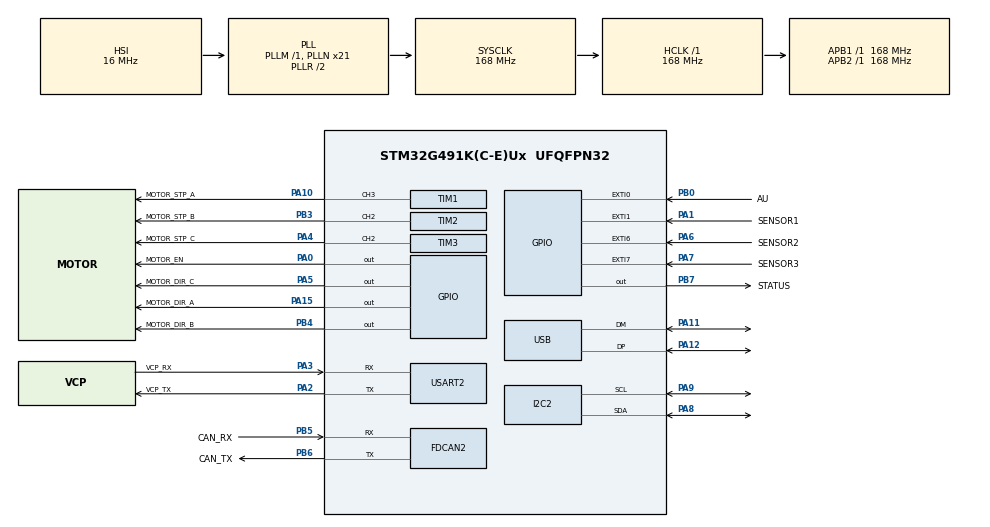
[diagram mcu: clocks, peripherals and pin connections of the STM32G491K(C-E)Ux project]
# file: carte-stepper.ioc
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FDCAN2.CalculateBaudRateNominal=3500000
FDCAN2.CalculateTimeBitNominal=285
FDCAN2.CalculateTimeQuantumNominal=95.23809523809524
I2C2.OwnAddress=0x69
I2C2.Timing=0x50916E9F
Mcu.Family=STM32G4
Mcu.Name=STM32G491K(C-E)Ux
Mcu.Package=UFQFPN32
NVIC.EXTI1_IRQn=true\:0\:0\:false\:false\:true\:true\:true\:true
NVIC.EXTI9_5_IRQn=true\:0\:0\:false\:false\:true\:true\:true\:true
NVIC.I2C2_ER_IRQn=true\:0\:0\:false\:false\:true\:true\:true\:true
NVIC.I2C2_EV_IRQn=true\:0\:0\:false\:false\:true\:true\:true\:true
NVIC.PriorityGroup=NVIC_PRIORITYGROUP_4
NVIC.TIM1_BRK_TIM15_IRQn=true\:0\:0\:false\:false\:true\:true\:true\:true
NVIC.TIM1_UP_TIM16_IRQn=true\:0\:0\:false\:false\:true\:true\:true\:true
NVIC.TIM20_UP_IRQn=true\:0\:0\:false\:false\:true\:true\:true\:true
NVIC.TIM2_IRQn=true\:0\:0\:false\:false\:true\:true\:true\:true
NVIC.TIM3_IRQn=true\:0\:0\:false\:false\:true\:true\:true\:true
NVIC.TIM4_IRQn=true\:0\:0\:false\:false\:true\:true\:true\:true
NVIC.TIM8_UP_IRQn=true\:0\:0\:false\:false\:true\:true\:true\:true
NVIC.USART2_IRQn=true\:0\:0\:false\:false\:true\:true\:true\:true
PA0.GPIO_Label=MOTOR_EN
PA0.Signal=GPIO_Output
PA1.GPIO_Label=SENSOR1
PA1.Signal=GPXTI1
PA10.GPIO_Label=MOTOR_STP_A
PA10.Signal=S_TIM1_CH3
PA11.Mode=Device
PA11.Signal=USB_DM
PA12.Mode=Device
PA12.Signal=USB_DP
PA13.Mode=Serial_Wire
PA13.Signal=SYS_JTMS-SWDIO
PA14.Mode=Serial_Wire
PA14.Signal=SYS_JTCK-SWCLK
PA15.GPIO_Label=MOTOR_DIR_A
PA15.Signal=GPIO_Output
PA2.GPIO_Label=VCP_TX
PA2.Mode=Asynchronous
PA2.Signal=USART2_TX
PA3.GPIO_Label=VCP_RX
PA3.Mode=Asynchronous
PA3.Signal=USART2_RX
PA4.GPIO_Label=MOTOR_STP_C
PA4.Signal=S_TIM3_CH2
PA5.GPIO_Label=MOTOR_DIR_C
PA5.Signal=GPIO_Output
PA6.GPIO_Label=SENSOR2
PA6.Signal=GPXTI6
PA7.GPIO_Label=SENSOR3
PA7.Signal=GPXTI7
PA8.Mode=I2C
PA8.Signal=I2C2_SDA
PA9.Mode=I2C
PA9.Signal=I2C2_SCL
PB0.GPIO_Label=AU
PB0.Signal=GPXTI0
PB3.GPIO_Label=MOTOR_STP_B
PB3.Signal=S_TIM2_CH2
PB4.GPIO_Label=MOTOR_DIR_B
PB4.Signal=GPIO_Output
PB5.GPIO_Label=CAN_RX
PB5.Mode=FDCAN_Activate
PB5.Signal=FDCAN2_RX
PB6.GPIO_Label=CAN_TX
PB6.Mode=FDCAN_Activate
PB6.Signal=FDCAN2_TX
PB7.GPIO_Label=STATUS
PB7.Signal=GPIO_Output
ProjectManager.HeapSize=0x200
ProjectManager.StackSize=0x400
ProjectManager.TargetToolchain=STM32CubeIDE
RCC.ADC12Freq_Value=168000000
RCC.ADC345Freq_Value=168000000
RCC.AHBFreq_Value=168000000
RCC.APB1Freq_Value=168000000
RCC.APB1TimFreq_Value=168000000
RCC.APB2Freq_Value=168000000
RCC.APB2TimFreq_Value=168000000
RCC.CortexFreq_Value=168000000
RCC.EXTERNAL_CLOCK_VALUE=12288000
RCC.HCLKFreq_Value=168000000
RCC.HSE_VALUE=8000000
RCC.HSI48_VALUE=48000000
RCC.HSI_VALUE=16000000
RCC.LSE_VALUE=32768
RCC.PLLN=21
RCC.SYSCLKFreq_VALUE=168000000
RCC.SYSCLKSource=RCC_SYSCLKSOURCE_PLLCLK
RCC.VCOOutputFreq_Value=336000000
SH.S_TIM1_CH3.0=TIM1_CH3,PWM Generation3 CH3
SH.S_TIM2_CH2.0=TIM2_CH2,PWM Generation2 CH2
SH.S_TIM3_CH2.0=TIM3_CH2,PWM Generation2 CH2
TIM1.Channel-PWM\ Generation3\ CH3=TIM_CHANNEL_3
TIM1.TIM_MasterOutputTrigger=TIM_TRGO_UPDATE
TIM2.Channel-PWM\ Generation2\ CH2=TIM_CHANNEL_2
TIM2.TIM_MasterOutputTrigger=TIM_TRGO_UPDATE
TIM3.Channel-PWM\ Generation2\ CH2=TIM_CHANNEL_2
TIM3.TIM_MasterOutputTrigger=TIM_TRGO_UPDATE
USART2.VirtualMode-Asynchronous=VM_ASYNC
VP_SYS_VS_DBSignals.Mode=DisableDeadBatterySignals
VP_TIM20_VS_ClockSourceITR.Mode=TriggerSource_ITR2
VP_TIM20_VS_ControllerModeClock.Mode=Clock Mode
VP_TIM4_VS_ClockSourceITR.Mode=TriggerSource_ITR0
VP_TIM4_VS_ControllerModeClock.Mode=Clock Mode
VP_TIM8_VS_ClockSourceITR.Mode=TriggerSource_ITR1
VP_TIM8_VS_ControllerModeClock.Mode=Clock Mode
board=custom

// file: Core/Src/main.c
/* USER CODE BEGIN Header */
/**
  ******************************************************************************
  * @file           : main.c
  * @brief          : Main program body
  ******************************************************************************
  * @attention
  *
  * Copyright (c) 2025 STMicroelectronics.
  * All rights reserved.
  *
  * This software is licensed under terms that can be found in the LICENSE file
  * in the root directory of this software component.
  * If no LICENSE file comes with this software, it is provided AS-IS.
  *
  ******************************************************************************
  */
/* USER CODE END Header */
#include "main.h"

/* USER CODE BEGIN Includes */
#include "stepper_control.h"
#include "stdbool.h"
#include "stdio.h"
/* USER CODE END Includes */

/* USER CODE BEGIN PD */

#define STEPPERS_AMNT 3

/* USER CODE END PD */

FDCAN_HandleTypeDef hfdcan2;

I2C_HandleTypeDef hi2c2;

TIM_HandleTypeDef htim1;
TIM_HandleTypeDef htim2;
TIM_HandleTypeDef htim3;
TIM_HandleTypeDef htim4;
TIM_HandleTypeDef htim8;
TIM_HandleTypeDef htim20;

UART_HandleTypeDef huart2;

PCD_HandleTypeDef hpcd_USB_FS;

void SystemClock_Config(void);
static void MX_GPIO_Init(void);
static void MX_FDCAN2_Init(void);
static void MX_I2C2_Init(void);
static void MX_TIM1_Init(void);
static void MX_TIM2_Init(void);
static void MX_TIM3_Init(void);
static void MX_USART2_UART_Init(void);
static void MX_USB_PCD_Init(void);
static void MX_TIM4_Init(void);
static void MX_TIM20_Init(void);
static void MX_TIM8_Init(void);

/* USER CODE BEGIN 0 */

int __io_putchar(char c) {
	HAL_UART_Transmit(&huart2, (uint8_t*)&c, 1, HAL_MAX_DELAY);
	return c;
}

int _write(int file, char *ptr, int len) {
	(void) file;
	HAL_UART_Transmit(&huart2, (uint8_t*) ptr, len, HAL_MAX_DELAY);
	return len;
}

stepper_config_t stepper_configs[STEPPERS_AMNT] = {
	{
		.handle = &htim1,
		.channel = TIM_CHANNEL_3,
		.channel_inverted = false,

		.dir_port = GPIOA,
		.dir_pin = GPIO_PIN_15,
		.dir_inverted = false,

		.clock = 168000000,
		.max_freq = 2000000,

		.kp = 30,
		.kd = 0,
		.ki = 10,
		.integral_max = 1000000,
	},{
		.handle = &htim2,
		.channel = TIM_CHANNEL_2,
		.channel_inverted = false,

		.dir_port = GPIOB,
		.dir_pin = GPIO_PIN_4,
		.dir_inverted = false,

		.clock = 168000000,
		.max_freq = 2000000,

		.kp = 30,
		.kd = 0,
		.ki = 10,
		.integral_max = 1000000,
	},{
		.handle = &htim3,
		.channel = TIM_CHANNEL_2,
		.channel_inverted = false,

		.dir_port = GPIOA,
		.dir_pin = GPIO_PIN_5,
		.dir_inverted = false,

		.clock = 168000000,
		.max_freq = 2000000,

		.kp = 30,
		.kd = 0,
		.ki = 10,
		.integral_max = 1000000,
	}
};

stepper_t steppers[STEPPERS_AMNT] = {0};

/* USER CODE END 0 */

int main(void)
{

  /* MCU Configuration--------------------------------------------------------*/

  /* Reset of all peripherals, Initializes the Flash interface and the Systick. */
  HAL_Init();

  /* Configure the system clock */
  SystemClock_Config();

  /* Initialize all configured peripherals */
  MX_GPIO_Init();
  MX_FDCAN2_Init();
  MX_I2C2_Init();
  MX_TIM1_Init();
  MX_TIM2_Init();
  MX_TIM3_Init();
  MX_USART2_UART_Init();
  MX_USB_PCD_Init();
  MX_TIM4_Init();
  MX_TIM20_Init();
  MX_TIM8_Init();
  /* USER CODE BEGIN 2 */
  printf("HAL init done\n\r");
  setup();
  printf("Setup done\n\r");
  /* USER CODE END 2 */

  /* Infinite loop */
  /* USER CODE BEGIN WHILE */
  while (1)
  {
	  loop();
    /* USER CODE END WHILE */

  }
}

void SystemClock_Config(void)
{
  RCC_OscInitTypeDef RCC_OscInitStruct = {0};
  RCC_ClkInitTypeDef RCC_ClkInitStruct = {0};

  /** Configure the main internal regulator output voltage
  */
  HAL_PWREx_ControlVoltageScaling(PWR_REGULATOR_VOLTAGE_SCALE1_BOOST);

  /** Initializes the RCC Oscillators according to the specified parameters
  * in the RCC_OscInitTypeDef structure.
  */
  RCC_OscInitStruct.OscillatorType = RCC_OSCILLATORTYPE_HSI|RCC_OSCILLATORTYPE_HSI48;
  RCC_OscInitStruct.HSIState = RCC_HSI_ON;
  RCC_OscInitStruct.HSICalibrationValue = RCC_HSICALIBRATION_DEFAULT;
  RCC_OscInitStruct.HSI48State = RCC_HSI48_ON;
  RCC_OscInitStruct.PLL.PLLState = RCC_PLL_ON;
  RCC_OscInitStruct.PLL.PLLSource = RCC_PLLSOURCE_HSI;
  RCC_OscInitStruct.PLL.PLLM = RCC_PLLM_DIV1;
  RCC_OscInitStruct.PLL.PLLN = 21;
  RCC_OscInitStruct.PLL.PLLP = RCC_PLLP_DIV2;
  RCC_OscInitStruct.PLL.PLLQ = RCC_PLLQ_DIV2;
  RCC_OscInitStruct.PLL.PLLR = RCC_PLLR_DIV2;
  if (HAL_RCC_OscConfig(&RCC_OscInitStruct) != HAL_OK)
  {
    Error_Handler();
  }

  /** Initializes the CPU, AHB and APB buses clocks
  */
  RCC_ClkInitStruct.ClockType = RCC_CLOCKTYPE_HCLK|RCC_CLOCKTYPE_SYSCLK
                              |RCC_CLOCKTYPE_PCLK1|RCC_CLOCKTYPE_PCLK2;
  RCC_ClkInitStruct.SYSCLKSource = RCC_SYSCLKSOURCE_PLLCLK;
  RCC_ClkInitStruct.AHBCLKDivider = RCC_SYSCLK_DIV1;
  RCC_ClkInitStruct.APB1CLKDivider = RCC_HCLK_DIV1;
  RCC_ClkInitStruct.APB2CLKDivider = RCC_HCLK_DIV1;

  if (HAL_RCC_ClockConfig(&RCC_ClkInitStruct, FLASH_LATENCY_4) != HAL_OK)
  {
    Error_Handler();
  }
}

static void MX_FDCAN2_Init(void)
{

  hfdcan2.Instance = FDCAN2;
  hfdcan2.Init.ClockDivider = FDCAN_CLOCK_DIV1;
  hfdcan2.Init.FrameFormat = FDCAN_FRAME_CLASSIC;
  hfdcan2.Init.Mode = FDCAN_MODE_NORMAL;
  hfdcan2.Init.AutoRetransmission = DISABLE;
  hfdcan2.Init.TransmitPause = DISABLE;
  hfdcan2.Init.ProtocolException = DISABLE;
  hfdcan2.Init.NominalPrescaler = 16;
  hfdcan2.Init.NominalSyncJumpWidth = 1;
  hfdcan2.Init.NominalTimeSeg1 = 1;
  hfdcan2.Init.NominalTimeSeg2 = 1;
  hfdcan2.Init.DataPrescaler = 1;
  hfdcan2.Init.DataSyncJumpWidth = 1;
  hfdcan2.Init.DataTimeSeg1 = 1;
  hfdcan2.Init.DataTimeSeg2 = 1;
  hfdcan2.Init.StdFiltersNbr = 0;
  hfdcan2.Init.ExtFiltersNbr = 0;
  hfdcan2.Init.TxFifoQueueMode = FDCAN_TX_FIFO_OPERATION;
  if (HAL_FDCAN_Init(&hfdcan2) != HAL_OK)
  {
    Error_Handler();
  }

}

static void MX_I2C2_Init(void)
{

  hi2c2.Instance = I2C2;
  hi2c2.Init.Timing = 0x50916E9F;
  hi2c2.Init.OwnAddress1 = 210;
  hi2c2.Init.AddressingMode = I2C_ADDRESSINGMODE_7BIT;
  hi2c2.Init.DualAddressMode = I2C_DUALADDRESS_DISABLE;
  hi2c2.Init.OwnAddress2 = 0;
  hi2c2.Init.OwnAddress2Masks = I2C_OA2_NOMASK;
  hi2c2.Init.GeneralCallMode = I2C_GENERALCALL_DISABLE;
  hi2c2.Init.NoStretchMode = I2C_NOSTRETCH_DISABLE;
  if (HAL_I2C_Init(&hi2c2) != HAL_OK)
  {
    Error_Handler();
  }

  /** Configure Analogue filter
  */
  if (HAL_I2CEx_ConfigAnalogFilter(&hi2c2, I2C_ANALOGFILTER_ENABLE) != HAL_OK)
  {
    Error_Handler();
  }

  /** Configure Digital filter
  */
  if (HAL_I2CEx_ConfigDigitalFilter(&hi2c2, 0) != HAL_OK)
  {
    Error_Handler();
  }

}

static void MX_TIM1_Init(void)
{

  TIM_MasterConfigTypeDef sMasterConfig = {0};
  TIM_OC_InitTypeDef sConfigOC = {0};
  TIM_BreakDeadTimeConfigTypeDef sBreakDeadTimeConfig = {0};

  htim1.Instance = TIM1;
  htim1.Init.Prescaler = 0;
  htim1.Init.CounterMode = TIM_COUNTERMODE_UP;
  htim1.Init.Period = 65535;
  htim1.Init.ClockDivision = TIM_CLOCKDIVISION_DIV1;
  htim1.Init.RepetitionCounter = 0;
  htim1.Init.AutoReloadPreload = TIM_AUTORELOAD_PRELOAD_DISABLE;
  if (HAL_TIM_PWM_Init(&htim1) != HAL_OK)
  {
    Error_Handler();
  }
  sMasterConfig.MasterOutputTrigger = TIM_TRGO_UPDATE;
  sMasterConfig.MasterOutputTrigger2 = TIM_TRGO2_RESET;
  sMasterConfig.MasterSlaveMode = TIM_MASTERSLAVEMODE_DISABLE;
  if (HAL_TIMEx_MasterConfigSynchronization(&htim1, &sMasterConfig) != HAL_OK)
  {
    Error_Handler();
  }
  sConfigOC.OCMode = TIM_OCMODE_PWM1;
  sConfigOC.Pulse = 0;
  sConfigOC.OCPolarity = TIM_OCPOLARITY_HIGH;
  sConfigOC.OCNPolarity = TIM_OCNPOLARITY_HIGH;
  sConfigOC.OCFastMode = TIM_OCFAST_DISABLE;
  sConfigOC.OCIdleState = TIM_OCIDLESTATE_RESET;
  sConfigOC.OCNIdleState = TIM_OCNIDLESTATE_RESET;
  if (HAL_TIM_PWM_ConfigChannel(&htim1, &sConfigOC, TIM_CHANNEL_3) != HAL_OK)
  {
    Error_Handler();
  }
  sBreakDeadTimeConfig.OffStateRunMode = TIM_OSSR_DISABLE;
  sBreakDeadTimeConfig.OffStateIDLEMode = TIM_OSSI_DISABLE;
  sBreakDeadTimeConfig.LockLevel = TIM_LOCKLEVEL_OFF;
  sBreakDeadTimeConfig.DeadTime = 0;
  sBreakDeadTimeConfig.BreakState = TIM_BREAK_DISABLE;
  sBreakDeadTimeConfig.BreakPolarity = TIM_BREAKPOLARITY_HIGH;
  sBreakDeadTimeConfig.BreakFilter = 0;
  sBreakDeadTimeConfig.BreakAFMode = TIM_BREAK_AFMODE_INPUT;
  sBreakDeadTimeConfig.Break2State = TIM_BREAK2_DISABLE;
  sBreakDeadTimeConfig.Break2Polarity = TIM_BREAK2POLARITY_HIGH;
  sBreakDeadTimeConfig.Break2Filter = 0;
  sBreakDeadTimeConfig.Break2AFMode = TIM_BREAK_AFMODE_INPUT;
  sBreakDeadTimeConfig.AutomaticOutput = TIM_AUTOMATICOUTPUT_DISABLE;
  if (HAL_TIMEx_ConfigBreakDeadTime(&htim1, &sBreakDeadTimeConfig) != HAL_OK)
  {
    Error_Handler();
  }
  HAL_TIM_MspPostInit(&htim1);

}

static void MX_TIM2_Init(void)
{

  TIM_MasterConfigTypeDef sMasterConfig = {0};
  TIM_OC_InitTypeDef sConfigOC = {0};

  htim2.Instance = TIM2;
  htim2.Init.Prescaler = 0;
  htim2.Init.CounterMode = TIM_COUNTERMODE_UP;
  htim2.Init.Period = 4294967295;
  htim2.Init.ClockDivision = TIM_CLOCKDIVISION_DIV1;
  htim2.Init.AutoReloadPreload = TIM_AUTORELOAD_PRELOAD_DISABLE;
  if (HAL_TIM_PWM_Init(&htim2) != HAL_OK)
  {
    Error_Handler();
  }
  sMasterConfig.MasterOutputTrigger = TIM_TRGO_UPDATE;
  sMasterConfig.MasterSlaveMode = TIM_MASTERSLAVEMODE_DISABLE;
  if (HAL_TIMEx_MasterConfigSynchronization(&htim2, &sMasterConfig) != HAL_OK)
  {
    Error_Handler();
  }
  sConfigOC.OCMode = TIM_OCMODE_PWM1;
  sConfigOC.Pulse = 0;
  sConfigOC.OCPolarity = TIM_OCPOLARITY_HIGH;
  sConfigOC.OCFastMode = TIM_OCFAST_DISABLE;
  if (HAL_TIM_PWM_ConfigChannel(&htim2, &sConfigOC, TIM_CHANNEL_2) != HAL_OK)
  {
    Error_Handler();
  }
  HAL_TIM_MspPostInit(&htim2);

}

static void MX_TIM3_Init(void)
{

  TIM_MasterConfigTypeDef sMasterConfig = {0};
  TIM_OC_InitTypeDef sConfigOC = {0};

  htim3.Instance = TIM3;
  htim3.Init.Prescaler = 0;
  htim3.Init.CounterMode = TIM_COUNTERMODE_UP;
  htim3.Init.Period = 65535;
  htim3.Init.ClockDivision = TIM_CLOCKDIVISION_DIV1;
  htim3.Init.AutoReloadPreload = TIM_AUTORELOAD_PRELOAD_DISABLE;
  if (HAL_TIM_PWM_Init(&htim3) != HAL_OK)
  {
    Error_Handler();
  }
  sMasterConfig.MasterOutputTrigger = TIM_TRGO_UPDATE;
  sMasterConfig.MasterSlaveMode = TIM_MASTERSLAVEMODE_DISABLE;
  if (HAL_TIMEx_MasterConfigSynchronization(&htim3, &sMasterConfig) != HAL_OK)
  {
    Error_Handler();
  }
  sConfigOC.OCMode = TIM_OCMODE_PWM1;
  sConfigOC.Pulse = 0;
  sConfigOC.OCPolarity = TIM_OCPOLARITY_HIGH;
  sConfigOC.OCFastMode = TIM_OCFAST_DISABLE;
  if (HAL_TIM_PWM_ConfigChannel(&htim3, &sConfigOC, TIM_CHANNEL_2) != HAL_OK)
  {
    Error_Handler();
  }
  HAL_TIM_MspPostInit(&htim3);

}

static void MX_TIM4_Init(void)
{

  TIM_SlaveConfigTypeDef sSlaveConfig = {0};
  TIM_MasterConfigTypeDef sMasterConfig = {0};

  htim4.Instance = TIM4;
  htim4.Init.Prescaler = 0;
  htim4.Init.CounterMode = TIM_COUNTERMODE_UP;
  htim4.Init.Period = 65535;
  htim4.Init.ClockDivision = TIM_CLOCKDIVISION_DIV1;
  htim4.Init.AutoReloadPreload = TIM_AUTORELOAD_PRELOAD_DISABLE;
  if (HAL_TIM_Base_Init(&htim4) != HAL_OK)
  {
    Error_Handler();
  }
  sSlaveConfig.SlaveMode = TIM_SLAVEMODE_EXTERNAL1;
  sSlaveConfig.InputTrigger = TIM_TS_ITR0;
  if (HAL_TIM_SlaveConfigSynchro(&htim4, &sSlaveConfig) != HAL_OK)
  {
    Error_Handler();
  }
  sMasterConfig.MasterOutputTrigger = TIM_TRGO_RESET;
  sMasterConfig.MasterSlaveMode = TIM_MASTERSLAVEMODE_DISABLE;
  if (HAL_TIMEx_MasterConfigSynchronization(&htim4, &sMasterConfig) != HAL_OK)
  {
    Error_Handler();
  }

}

static void MX_TIM8_Init(void)
{

  TIM_SlaveConfigTypeDef sSlaveConfig = {0};
  TIM_MasterConfigTypeDef sMasterConfig = {0};

  htim8.Instance = TIM8;
  htim8.Init.Prescaler = 0;
  htim8.Init.CounterMode = TIM_COUNTERMODE_UP;
  htim8.Init.Period = 65535;
  htim8.Init.ClockDivision = TIM_CLOCKDIVISION_DIV1;
  htim8.Init.RepetitionCounter = 0;
  htim8.Init.AutoReloadPreload = TIM_AUTORELOAD_PRELOAD_DISABLE;
  if (HAL_TIM_Base_Init(&htim8) != HAL_OK)
  {
    Error_Handler();
  }
  sSlaveConfig.SlaveMode = TIM_SLAVEMODE_EXTERNAL1;
  sSlaveConfig.InputTrigger = TIM_TS_ITR1;
  if (HAL_TIM_SlaveConfigSynchro(&htim8, &sSlaveConfig) != HAL_OK)
  {
    Error_Handler();
  }
  sMasterConfig.MasterOutputTrigger = TIM_TRGO_RESET;
  sMasterConfig.MasterOutputTrigger2 = TIM_TRGO2_RESET;
  sMasterConfig.MasterSlaveMode = TIM_MASTERSLAVEMODE_DISABLE;
  if (HAL_TIMEx_MasterConfigSynchronization(&htim8, &sMasterConfig) != HAL_OK)
  {
    Error_Handler();
  }

}

static void MX_TIM20_Init(void)
{

  TIM_SlaveConfigTypeDef sSlaveConfig = {0};
  TIM_MasterConfigTypeDef sMasterConfig = {0};

  htim20.Instance = TIM20;
  htim20.Init.Prescaler = 0;
  htim20.Init.CounterMode = TIM_COUNTERMODE_UP;
  htim20.Init.Period = 65535;
  htim20.Init.ClockDivision = TIM_CLOCKDIVISION_DIV1;
  htim20.Init.RepetitionCounter = 0;
  htim20.Init.AutoReloadPreload = TIM_AUTORELOAD_PRELOAD_DISABLE;
  if (HAL_TIM_Base_Init(&htim20) != HAL_OK)
  {
    Error_Handler();
  }
  sSlaveConfig.SlaveMode = TIM_SLAVEMODE_EXTERNAL1;
  sSlaveConfig.InputTrigger = TIM_TS_ITR2;
  if (HAL_TIM_SlaveConfigSynchro(&htim20, &sSlaveConfig) != HAL_OK)
  {
    Error_Handler();
  }
  sMasterConfig.MasterOutputTrigger = TIM_TRGO_RESET;
  sMasterConfig.MasterOutputTrigger2 = TIM_TRGO2_RESET;
  sMasterConfig.MasterSlaveMode = TIM_MASTERSLAVEMODE_DISABLE;
  if (HAL_TIMEx_MasterConfigSynchronization(&htim20, &sMasterConfig) != HAL_OK)
  {
    Error_Handler();
  }

}

static void MX_USART2_UART_Init(void)
{

  huart2.Instance = USART2;
  huart2.Init.BaudRate = 115200;
  huart2.Init.WordLength = UART_WORDLENGTH_8B;
  huart2.Init.StopBits = UART_STOPBITS_1;
  huart2.Init.Parity = UART_PARITY_NONE;
  huart2.Init.Mode = UART_MODE_TX_RX;
  huart2.Init.HwFlowCtl = UART_HWCONTROL_NONE;
  huart2.Init.OverSampling = UART_OVERSAMPLING_16;
  huart2.Init.OneBitSampling = UART_ONE_BIT_SAMPLE_DISABLE;
  huart2.Init.ClockPrescaler = UART_PRESCALER_DIV1;
  huart2.AdvancedInit.AdvFeatureInit = UART_ADVFEATURE_NO_INIT;
  if (HAL_UART_Init(&huart2) != HAL_OK)
  {
    Error_Handler();
  }
  if (HAL_UARTEx_SetTxFifoThreshold(&huart2, UART_TXFIFO_THRESHOLD_1_8) != HAL_OK)
  {
    Error_Handler();
  }
  if (HAL_UARTEx_SetRxFifoThreshold(&huart2, UART_RXFIFO_THRESHOLD_1_8) != HAL_OK)
  {
    Error_Handler();
  }
  if (HAL_UARTEx_DisableFifoMode(&huart2) != HAL_OK)
  {
    Error_Handler();
  }

}

static void MX_USB_PCD_Init(void)
{

  hpcd_USB_FS.Instance = USB;
  hpcd_USB_FS.Init.dev_endpoints = 8;
  hpcd_USB_FS.Init.speed = PCD_SPEED_FULL;
  hpcd_USB_FS.Init.phy_itface = PCD_PHY_EMBEDDED;
  hpcd_USB_FS.Init.Sof_enable = DISABLE;
  hpcd_USB_FS.Init.low_power_enable = DISABLE;
  hpcd_USB_FS.Init.lpm_enable = DISABLE;
  hpcd_USB_FS.Init.battery_charging_enable = DISABLE;
  if (HAL_PCD_Init(&hpcd_USB_FS) != HAL_OK)
  {
    Error_Handler();
  }

}

static void MX_GPIO_Init(void)
{
  GPIO_InitTypeDef GPIO_InitStruct = {0};

  /* GPIO Ports Clock Enable */
  __HAL_RCC_GPIOA_CLK_ENABLE();
  __HAL_RCC_GPIOB_CLK_ENABLE();

  /*Configure GPIO pin Output Level */
  HAL_GPIO_WritePin(GPIOA, MOTOR_EN_Pin|MOTOR_DIR_C_Pin|MOTOR_DIR_A_Pin, GPIO_PIN_RESET);

  /*Configure GPIO pin Output Level */
  HAL_GPIO_WritePin(GPIOB, MOTOR_DIR_B_Pin|STATUS_Pin, GPIO_PIN_RESET);

  /*Configure GPIO pins : MOTOR_EN_Pin MOTOR_DIR_C_Pin MOTOR_DIR_A_Pin */
  GPIO_InitStruct.Pin = MOTOR_EN_Pin|MOTOR_DIR_C_Pin|MOTOR_DIR_A_Pin;
  GPIO_InitStruct.Mode = GPIO_MODE_OUTPUT_PP;
  GPIO_InitStruct.Pull = GPIO_NOPULL;
  GPIO_InitStruct.Speed = GPIO_SPEED_FREQ_LOW;
  HAL_GPIO_Init(GPIOA, &GPIO_InitStruct);

  /*Configure GPIO pins : SENSOR1_Pin SENSOR2_Pin SENSOR3_Pin */
  GPIO_InitStruct.Pin = SENSOR1_Pin|SENSOR2_Pin|SENSOR3_Pin;
  GPIO_InitStruct.Mode = GPIO_MODE_IT_RISING;
  GPIO_InitStruct.Pull = GPIO_NOPULL;
  HAL_GPIO_Init(GPIOA, &GPIO_InitStruct);

  /*Configure GPIO pin : AU_Pin */
  GPIO_InitStruct.Pin = AU_Pin;
  GPIO_InitStruct.Mode = GPIO_MODE_IT_RISING;
  GPIO_InitStruct.Pull = GPIO_NOPULL;
  HAL_GPIO_Init(AU_GPIO_Port, &GPIO_InitStruct);

  /*Configure GPIO pins : MOTOR_DIR_B_Pin STATUS_Pin */
  GPIO_InitStruct.Pin = MOTOR_DIR_B_Pin|STATUS_Pin;
  GPIO_InitStruct.Mode = GPIO_MODE_OUTPUT_PP;
  GPIO_InitStruct.Pull = GPIO_NOPULL;
  GPIO_InitStruct.Speed = GPIO_SPEED_FREQ_LOW;
  HAL_GPIO_Init(GPIOB, &GPIO_InitStruct);

  /* EXTI interrupt init*/
  HAL_NVIC_SetPriority(EXTI1_IRQn, 0, 0);
  HAL_NVIC_EnableIRQ(EXTI1_IRQn);

  HAL_NVIC_SetPriority(EXTI9_5_IRQn, 0, 0);
  HAL_NVIC_EnableIRQ(EXTI9_5_IRQn);

}

void Error_Handler(void)
{
  __disable_irq();
  while (1)
  {
  }
}
